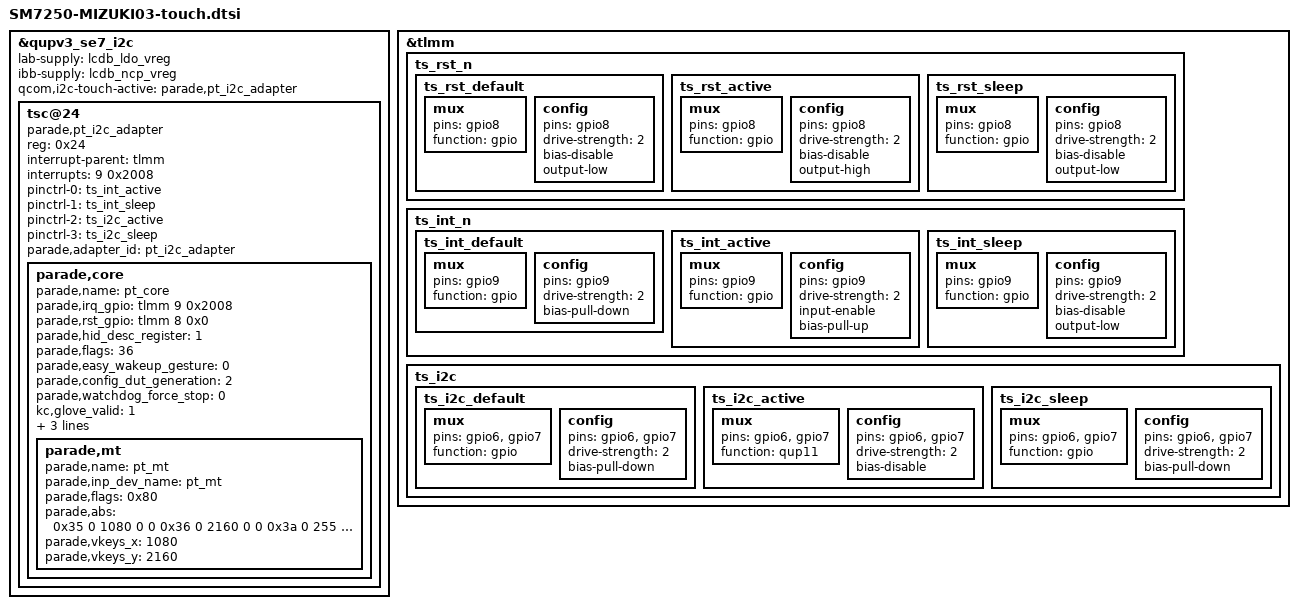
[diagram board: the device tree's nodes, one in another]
/*
 * This software is contributed or developed by KYOCERA Corporation.
 * (C) 2020 KYOCERA Corporation
 *
 * This program is free software; you can redistribute it and/or modify
 * it under the terms of the GNU General Public License version 2 and
 * only version 2 as published by the Free Software Foundation.
 *
 * This program is distributed in the hope that it will be useful,
 * but WITHOUT ANY WARRANTY; without even the implied warranty of
 * MERCHANTABILITY or FITNESS FOR A PARTICULAR PURPOSE.  See the
 * GNU General Public License for more details.
 */

&qupv3_se7_i2c {
	#address-cells = <1>;
	#size-cells = <0>;

	status = "ok";

	lab-supply = <&lcdb_ldo_vreg>;
	ibb-supply = <&lcdb_ncp_vreg>;

	qcom,i2c-touch-active = "parade,pt_i2c_adapter";

	tsc@24 {
		compatible = "parade,pt_i2c_adapter";
		reg = <0x24>;
		interrupt-parent = <&tlmm>;
		interrupts = <9 0x2008>;
		pinctrl-names = "pmx_ts_active", "pmx_ts_sleep", "ts_i2c_active", "ts_i2c_sleep";
		pinctrl-0 = <&ts_int_active>;
		pinctrl-1 = <&ts_int_sleep>;
		pinctrl-2 = <&ts_i2c_active>;
		pinctrl-3 = <&ts_i2c_sleep>;

		parade,adapter_id = "pt_i2c_adapter";

		parade,core {
			parade,name = "pt_core";

			parade,irq_gpio = <&tlmm 9 0x2008>;
			parade,rst_gpio = <&tlmm 8 0x0>;


			parade,hid_desc_register = <1>;
			parade,flags = <36>;
			parade,easy_wakeup_gesture = <0>;
			parade,config_dut_generation = <2>;
			parade,watchdog_force_stop = <0>;
			kc,glove_valid = <1>;
			kc,easywake_valid = <0>;
			kc,fw_type = <0x03>;

			panel = <&dsi_auo_fhd_2160_video>;

			parade,mt {
				parade,name = "pt_mt";
				parade,inp_dev_name = "pt_mt";
				parade,flags = <0x80>;
				parade,abs =
					/* ABS_MT_POSITION_X, PT_ABS_MIN_X, PT_ABS_MAX_X, 0, 0 */
					<0x35 0 1080 0 0
					/* ABS_MT_POSITION_Y, PT_ABS_MIN_Y, PT_ABS_MAX_Y, 0, 0 */
					0x36 0 2160 0 0
					/* ABS_MT_PRESSURE, PT_ABS_MIN_P, PT_ABS_MAX_P, 0, 0 */
					0x3a 0 255 0 0
					/* PT_IGNORE_VALUE, PT_ABS_MIN_W, PT_ABS_MAX_W, 0, 0 */
					0xffff 0 255 0 0
					/* ABS_MT_TRACKING_ID, PT_ABS_MIN_T, PT_ABS_MAX_T, 0, 0 */
					0x39 0 15 0 0
					/* ABS_MT_TOUCH_MAJOR, 0, 255, 0, 0 */
					0x30 0 255 0 0
					/* ABS_MT_TOUCH_MINOR, 0, 255, 0, 0 */
					0x31 0 255 0 0
					/* ABS_MT_ORIENTATION, -127, 127, 0, 0 */
					0x34 0xffffff81 127 0 0
					/* ABS_MT_TOOL_TYPE, 0, MT_TOOL_MAX, 0, 0 */
					0x37 0 1 0 0
					/* ABS_DISTANCE, 0, 255, 0, 0 */
					0x19 0 255 0 0>;

				parade,vkeys_x = <1080>;
				parade,vkeys_y = <2160>;

			};
		};
	};

};

&tlmm {
	ts_rst_n {
		ts_rst_default: ts_rst_default {
			mux {
				pins = "gpio8";
				function = "gpio";
			};

			config {
				pins = "gpio8";
				drive-strength = <2>;
				bias-disable;
				output-low;
			};
		};
		ts_rst_active: ts_rst_active {
			mux {
				pins = "gpio8";
				function = "gpio";
			};

			config {
				pins = "gpio8";
				drive-strength = <2>;
				bias-disable;
				output-high;
			};
		};
		ts_rst_sleep: ts_rst_sleep {
			mux {
				pins = "gpio8";
				function = "gpio";
			};

			config {
				pins = "gpio8";
				drive-strength = <2>;
				bias-disable;
				output-low;
			};
		};
	};

	ts_int_n {
		ts_int_default: ts_int_default {
			mux {
				pins = "gpio9";
				function = "gpio";
			};

			config {
				pins = "gpio9";
				drive-strength = <2>;
				bias-pull-down;
			};
		};
		ts_int_active: ts_int_active {
			mux {
				pins = "gpio9";
				function = "gpio";
			};

			config {
				pins = "gpio9";
				drive-strength = <2>;
				input-enable;
				bias-pull-up;
			};
		};
		ts_int_sleep: ts_int_sleep {
			mux {
				pins = "gpio9";
				function = "gpio";
			};

			config {
				pins = "gpio9";
				drive-strength = <2>;
				bias-disable;
				output-low;
			};
		};
	};

    ts_i2c {
        ts_i2c_default: ts_i2c_default {
            mux {
                pins = "gpio6", "gpio7";
                function = "gpio";
            };
            config {
                pins = "gpio6", "gpio7";
                drive-strength = <2>;
                bias-pull-down;
            };
        };
        ts_i2c_active: ts_i2c_active {
            mux {
                pins = "gpio6", "gpio7";
                function = "qup11";
            };
            config {
                pins = "gpio6", "gpio7";
                drive-strength = <2>;
                bias-disable;
            };
        };
        ts_i2c_sleep: ts_i2c_sleep {
            mux {
                pins = "gpio6", "gpio7";
                function = "gpio";
            };
            config {
                pins = "gpio6", "gpio7";
                drive-strength = <2>;
                bias-pull-down;
            };
        };
    };
};
